# ATtiny10 register map
Vendor: Atmel; File version: 1.0
CPU: other r0p0, little endian, no MPU, no FPU, 4 interrupt priority bits
Registers are 8-bit, read-write, reset 0x0 unless marked. A register's access mark holds for its fields unless they carry their own. Offsets are from the block's base; lines under a group give offsets from that group; [hi:lo] are bit positions; {n}, {i} and the like mark numbered series; 'fields as' and 'values as' point back to an identical list; <NAME> marks a mode.

## Memory map
0x00800000 PORTB blocks up to offset 0xD — I/O Port
0x00800010 EXINT size 0x6 — External Interrupts
0x00800017 AC blocks up to offset 0x9 — Analog Comparator
0x00800017 ADC blocks up to offset 0x7 — Analog-to-Digital Converter
0x00800022 TC0 size 0xE — Timer/Counter, 16-bit
0x00800031 WDT size 0x1 — Watchdog Timer
0x00800032 CPU blocks up to offset 0xE — CPU Registers

## Interrupts
0 RESET (CPU) — External Reset, Power-on Reset and Watchdog Reset
1 INT0 (CPU) — External Interrupt Request 0
2 PCINT0 (CPU) — Pin Change Interrupt Request 0
3 TIM0_CAPT (CPU) — Timer/Counter0 Input Capture
4 TIM0_OVF (CPU) — Timer/Counter0 Overflow
5 TIM0_COMPA (CPU) — Timer/Counter Compare Match A
6 TIM0_COMPB (CPU) — Timer/Counter Compare Match B
7 ANA_COMP (CPU) — Analog Comparator
8 WDT (CPU) — Watchdog Time-out
9 VLM (CPU) — Vcc Voltage Level Monitor
10 ADC (CPU) — ADC Conversion Complete

## AC — Analog Comparator
Base 0x00800017
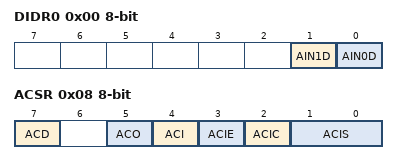
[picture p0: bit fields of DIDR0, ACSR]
0x00 DIDR0
  [1] AIN1D — AIN1 Digital Input Disable
  [0] AIN0D — AIN0 Digital Input Disable
0x08 ACSR — Analog Comparator Control And Status Register
  [7] ACD — Analog Comparator Disable
  [5] ACO — Analog Compare Output
  [4] ACI — Analog Comparator Interrupt Flag
  [3] ACIE — Analog Comparator Interrupt Enable
  [2] ACIC — Analog Comparator Input Capture Enable
  [1:0] ACIS — Analog Comparator Interrupt Mode Select bits
    0=INTERRUPT_ON_TOGGLE; 2=INTERRUPT_ON_FALLING_EDGE; 3=INTERRUPT_ON_RISING_EDGE

## ADC — Analog-to-Digital Converter
Base 0x00800017
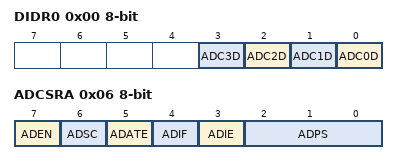
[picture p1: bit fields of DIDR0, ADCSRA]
0x00 DIDR0 — Digital Input Disable Register
  [n] ADC{n}D (n=0..3)
0x02 ADCL — ADC Data Register
0x04 ADMUX — The ADC multiplexer Selection Register
  [1:0] MUX — Analog Channel Selection Bits
0x05 ADCSRB — The ADC Control and Status register B
  [2:0] ADTS — ADC Auto Trigger Source bits
    0=FREE_RUNNING_MODE; 1=ANALOG_COMPARATOR; 2=EXTERNAL_INTERRUPT_REQUEST_0; 3=TIMER_COUNTER0_COMPARE_MATCH_A; 4=TIMER_COUNTER0_OVERFLOW; 5=TIMER_COUNTER0_COMPARE_MATCH_B; 6=PIN_CHANGE_INTERRUPT_0_REQUEST; 7=TIMER_COUNTER0_CAPTURE_EVENT
0x06 ADCSRA — The ADC Control and Status register A
  [7] ADEN — ADC Enable
  [6] ADSC — ADC Start Conversion
  [5] ADATE — ADC Auto Trigger Enable
  [4] ADIF — ADC Interrupt Flag
  [3] ADIE — ADC Interrupt Enable
  [2:0] ADPS — ADC Prescaler Select Bits
    1=2; 2=4; 3=8; 4=16; 5=32; 6=64; 7=128

## CPU — CPU Registers
Base 0x00800032
0x00 NVMCSR — Non-Volatile Memory Control and Status Register
  [7] NVMBSY — Non-Volatile Memory Busy
0x01 NVMCMD — Non-Volatile Memory Command
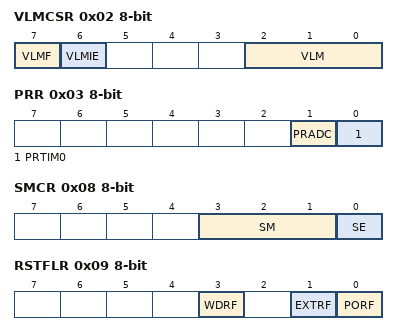
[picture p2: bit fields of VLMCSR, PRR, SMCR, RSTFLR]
0x02 VLMCSR — Vcc Level Monitoring Control and Status Register
  [7] VLMF — VLM Flag
  [6] VLMIE — VLM Interrupt Enable
  [2:0] VLM — Trigger Level of Voltage Level Monitor bits
0x03 PRR — Power Reduction Register
  [1] PRADC — Power Reduction ADC
  [0] PRTIM0 — Power Reduction Timer/Counter0
0x04 CLKPSR — Clock Prescale Register
  [3:0] CLKPS — Clock Prescaler Select Bits
    0=1; 1=2; 2=4; 3=8; 4=16; 5=32; 6=64; 7=128; 8=256
0x05 CLKMSR — Clock Main Settings Register
  [1:0] CLKMS — Clock Main Select Bits
0x07 OSCCAL — Oscillator Calibration Value
0x08 SMCR — Sleep Mode Control Register
  [3:1] SM — Sleep Mode Select Bits
    0=IDLE; 1=ADC (ADC Noise Reduction); 2=PDOWN (Power Down); 4=STDBY (Standby)
  [0] SE — Sleep Enable
0x09 RSTFLR — Reset Flag Register
  [3] WDRF — Watchdog Reset Flag
  [1] EXTRF — External Reset Flag
  [0] PORF — Power-on Reset Flag
0x0A CCP — Configuration Change Protection
0x0B SP 16-bit (reset mask 0xFF) — Stack Pointer
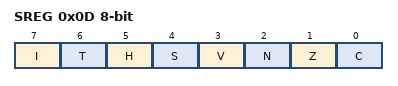
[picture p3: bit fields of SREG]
0x0D SREG — Status Register
  [7] I — Global Interrupt Enable
  [6] T — Bit Copy Storage
  [5] H — Half Carry Flag
  [4] S — Sign Bit
  [3] V — Two's Complement Overflow Flag
  [2] N — Negative Flag
  [1] Z — Zero Flag
  [0] C — Carry Flag

## EXINT — External Interrupts
Base 0x00800010
0x00 PCMSK — Pin Change Mask Register
  [3:0] PCINT — Pin Change Enable Masks
0x01 PCIFR — Pin Change Interrupt Flag Register
  [0] PCIF0 — Pin Change Interrupt Flag 0
0x02 PCICR — Pin Change Interrupt Control Register
  [0] PCIE0 — Pin Change Interrupt Enable 0
0x03 EIMSK — External Interrupt Mask register
  [0] INT0 — External Interrupt Request 0 Enable
0x04 EIFR — External Interrupt Flag register
  [0] INTF0 — External Interrupt Flag 0
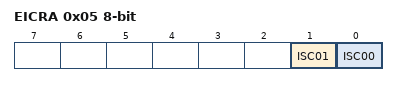
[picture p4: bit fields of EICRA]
0x05 EICRA — External Interrupt Control Register A
  [1] ISC01 — Interrupt Sense Control 0 Bit 1
  [0] ISC00 — Interrupt Sense Control 0 Bit 0

## PORTB — I/O Port
Base 0x00800000
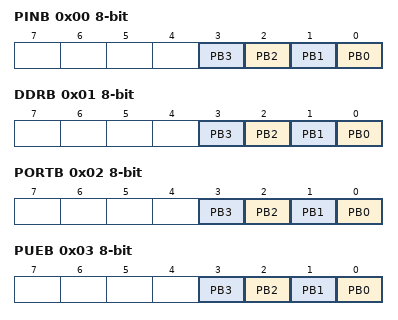
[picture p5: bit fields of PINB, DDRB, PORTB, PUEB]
0x00 PINB — Port B Data register
  [n] PB{n} (n=0..3) — Pin B{n}
0x01 DDRB — Data Direction Register, Port B
  [n] PB{n} (n=0..3) — Pin B{n}
0x02 PORTB — Input Pins, Port B
  [n] PB{n} (n=0..3) — Pin B{n}
0x03 PUEB — Pull-up Enable Control Register
  [n] PB{n} (n=0..3) — Pin B{n}
0x0C PORTCR — Port Control Register
  [1] BBMB — Break-Before-Make Mode Enable

## TC0 — Timer/Counter, 16-bit
Base 0x00800022
0x00 ICR0 16-bit (reset mask 0xFF) — Input Capture Register Bytes
0x02 OCR0B 16-bit (reset mask 0xFF) — Timer/Counter0 Output Compare Register B
0x04 OCR0A 16-bit (reset mask 0xFF) — Timer/Counter 0 Output Compare Register A
0x06 TCNT0 16-bit (reset mask 0xFF) — Timer/Counter0
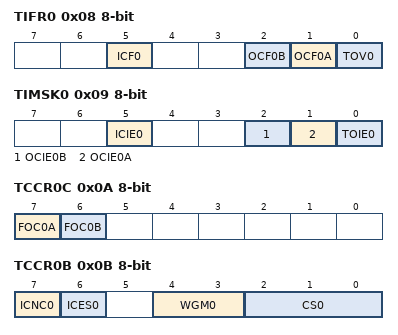
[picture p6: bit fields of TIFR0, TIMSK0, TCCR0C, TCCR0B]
0x08 TIFR0 — Overflow Interrupt Enable
  [5] ICF0 — Input Capture Flag
  [2] OCF0B — Timer Output Compare Flag 0B
  [1] OCF0A — Timer Output Compare Flag 0A
  [0] TOV0 — Timer Overflow Flag
0x09 TIMSK0 — Timer Interrupt Mask Register 0
  [5] ICIE0 — Input Capture Interrupt Enable
  [2] OCIE0B — Output Compare B Match Interrupt Enable
  [1] OCIE0A — Output Compare A Match Interrupt Enable
  [0] TOIE0 — Overflow Interrupt Enable
0x0A TCCR0C — Timer/Counter 0 Control Register C
  [7] FOC0A — Force Output Compare for Channel A
  [6] FOC0B — Force Output Compare for Channel B
0x0B TCCR0B — Timer/Counter 0 Control Register B
  [7] ICNC0 — Input Capture Noise Canceler
  [6] ICES0 — Input Capture Edge Select
  [4:3] WGM0 — Waveform Generation Mode
  [2:0] CS0 — Clock Select
    0=NO_CLOCK_SOURCE_STOPPED; 1=RUNNING_NO_PRESCALING; 2=RUNNING_CLK_8; 3=RUNNING_CLK_64; 4=RUNNING_CLK_256; 5=RUNNING_CLK_1024; 6=RUNNING_EXTCLK_TN_FALLING_EDGE; 7=RUNNING_EXTCLK_TN_RISING_EDGE
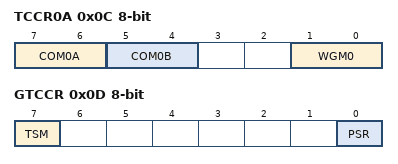
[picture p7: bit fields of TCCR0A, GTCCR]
0x0C TCCR0A — Timer/Counter 0 Control Register A
  [7:6] COM0A — Compare Output Mode for Channel A bits
  [5:4] COM0B — Compare Output Mode for Channel B bits
  [1:0] WGM0 — Waveform Generation Mode
0x0D GTCCR — General Timer/Counter Control Register
  [7] TSM — Timer Synchronization Mode
  [0] PSR — Prescaler Reset

## WDT — Watchdog Timer
Base 0x00800031
0x00 WDTCSR — Watchdog Timer Control and Status Register
  [7] WDIF — Watchdog Timer Interrupt Flag
  [6] WDIE — Watchdog Timer Interrupt Enable
  [3] WDE — Watch Dog Enable
  [5:0] WDP — Watchdog Timer Prescaler Bits
    0=OSCILLATOR_CYCLES_2K; 1=OSCILLATOR_CYCLES_4K; 2=OSCILLATOR_CYCLES_8K; 3=OSCILLATOR_CYCLES_16K; 4=OSCILLATOR_CYCLES_32K; 5=OSCILLATOR_CYCLES_64K; 6=OSCILLATOR_CYCLES_128K; 7=OSCILLATOR_CYCLES_256K
